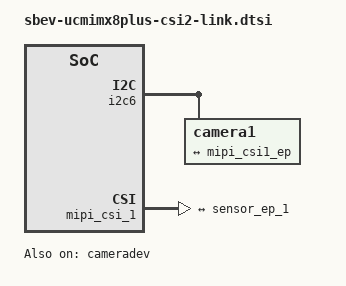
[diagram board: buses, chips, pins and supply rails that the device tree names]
&i2c6 {
	#address-cells = <1>;
	#size-cells = <0>;
	status = "okay";

	camera1: camera1@i2c {
		csi_id = <0x01>;
		status = "okay";

		port {
			sensor_ep_1: endpoint {
				data-lanes = <1 2 3 4>;
				clock-lanes = <0>;
				link-frequencies = /bits/ 64 <600000000>;
				max-lane-frequency = /bits/ 64 <600000000>;
				max-pixel-frequency = /bits/ 64 <266000000>;
				max-data-rate = /bits/ 64 <0>;

				remote-endpoint = <&mipi_csi1_ep>;
			};
		};
	};
};

&mipi_csi_1 {
	#address-cells = <1>;
	#size-cells = <0>;
	status = "okay";

	port@1 {
		reg = <1>;
		mipi_csi1_ep: endpoint {
			remote-endpoint = <&sensor_ep_1>;
			data-lanes = <4>;
			csis-hs-settle = <16>;
		};
	};
};

&cameradev {
	status = "okay";
};
